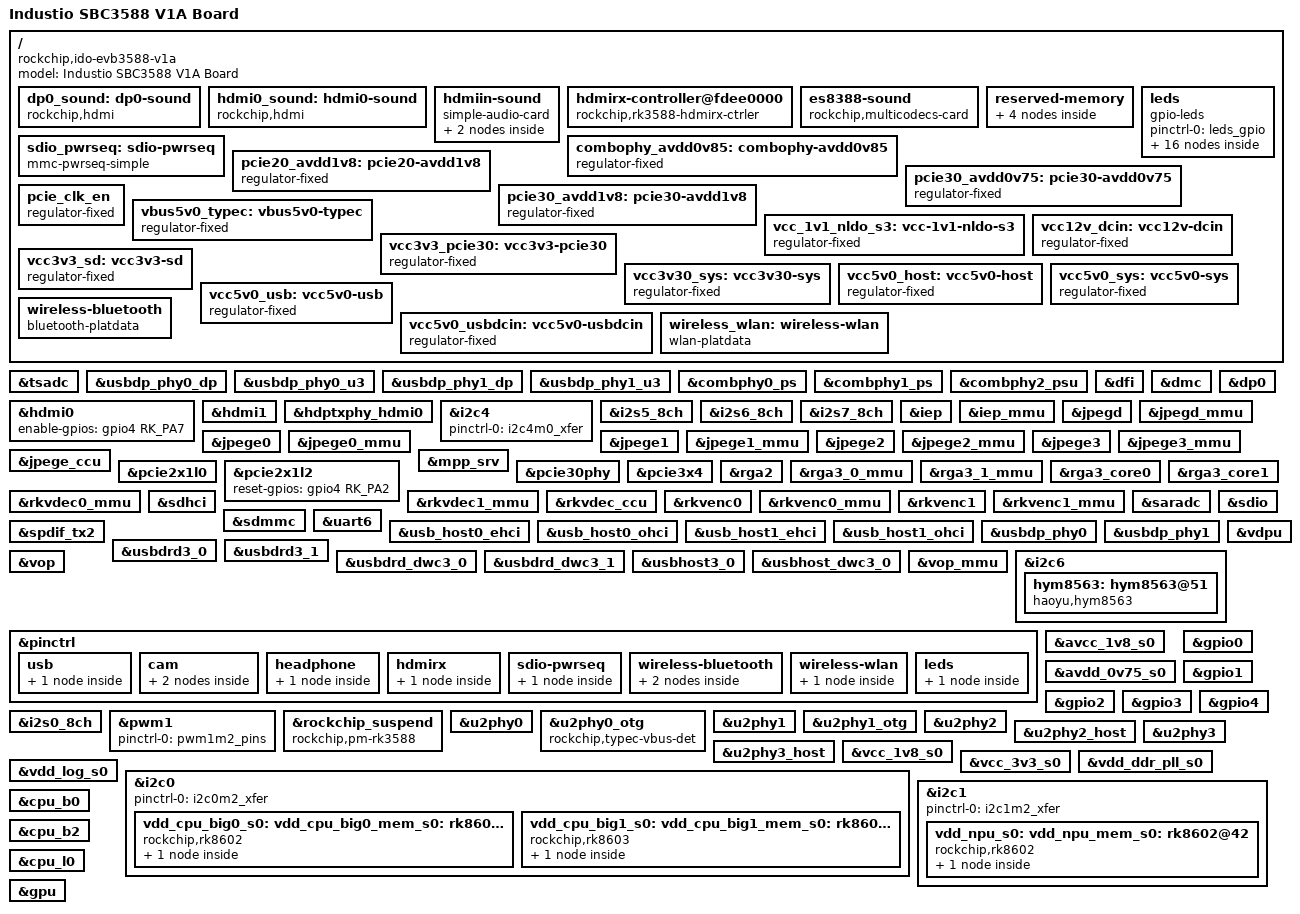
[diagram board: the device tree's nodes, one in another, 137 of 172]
// SPDX-License-Identifier: (GPL-2.0+ OR MIT)
/dts-v1/;
#include "rk3588.dtsi"
#include "rk3588-rk806-single.dtsi"

/ {
	model = "Industio SBC3588 V1A Board";
	compatible = "rockchip,ido-evb3588-v1a", "rockchip,rk3588";

	dp0_sound: dp0-sound {
	        status = "okay";
	        compatible = "rockchip,hdmi";
	        rockchip,card-name = "rockchip,dp0";
	        rockchip,mclk-fs = <512>;
	        rockchip,cpu = <&spdif_tx2>;
	        rockchip,codec = <&dp0 0x01>;
	        rockchip,jack-det;
	    };

	hdmi0_sound: hdmi0-sound {
	        status = "okay";
	        compatible = "rockchip,hdmi";
	        rockchip,mclk-fs = <128>;
	        rockchip,card-name = "rockchip-hdmi0";
	        rockchip,cpu = <&i2s5_8ch>;
	        rockchip,codec = <&hdmi0>;
	        rockchip,jack-det;
	    };

	hdmiin-sound {
	        compatible = "simple-audio-card";
	        simple-audio-card,format = "i2s";
	        simple-audio-card,name = "rockchip,hdmiin";
	        simple-audio-card,bitclock-master = <455>;
	        simple-audio-card,frame-master = <455>;
	        status = "okay";

	        simple-audio-card,cpu {
	            sound-dai = <456>;
	        };

	        simple-audio-card,codec {
	            sound-dai = <457>;
	            phandle = <0x1c7>;
	        };
	    };

	hdmirx-controller@fdee0000 {
	        compatible = "rockchip,rk3588-hdmirx-ctrler", "rockchip,hdmirx-ctrler";
	        reg = <0x00 0xfdee0000 0x00 0x6000>;
	        reg-names = "hdmirx_regs";
	        power-domains = <81 26>;
	        rockchip,grf = <187>;
	        rockchip,vo1_grf = <192>;
	        interrupts = <0x00 0xb1 0x04 0x00 0x1b4 0x04 0x00 0xb3 0x04>;
	        interrupt-names = "cec", "hdmi", "dma";
	        clocks = <0x02 538 0x02 543 0x02 690 0x02 539 0x02 540 0x02 562 0x05>;
	        clock-names = "aclk", "audio", "cr_para", "pclk", "ref", "hclk_s_hdmirx", "hclk_vo1";
	        resets = <0x02 985 0x02 986 0x02 987 0x02 951>;
	        reset-names = "rst_a", "rst_p", "rst_ref", "rst_biu";
	        pinctrl-0 = <&hdmim1_rx &hdmirx_det>;
	        pinctrl-names = "default";
	        status = "okay";
	        hpd-trigger-level = <0x01>;
	        hdmirx-det-gpios = <&gpio1 RK_PD5 GPIO_ACTIVE_LOW>;
	    };

	es8388-sound {
	        status = "okay";
	        compatible = "rockchip,multicodecs-card";
	        rockchip,card-name = "rockchip-es8388";
	        hp-det-gpio = <&gpio1 RK_PC4 GPIO_ACTIVE_HIGH>;
	        io-channels = <&saradc 0x03>;
	        io-channel-names = "adc-detect";
	        keyup-threshold-microvolt = <970000>;
	        poll-interval = <100>;
	        spk-con-gpio = <0x1ba 0x01 0x01>;
	        hp-con-gpio = <0x16d 0x1a 0x00>;
	        rockchip,format = "i2s";
	        rockchip,mclk-fs = <256>;
	        rockchip,cpu = <&i2s0_8ch>;
	        rockchip,codec = <459>;
	        rockchip,audio-routing = "Headphone", "LOUT1", "Headphone", "ROUT1", "Speaker", "LOUT2", "Speaker", "ROUT2", "Headphone", "Headphone Power", "Headphone", "Headphone Power", "Speaker", "Speaker Power", "Speaker", "Speaker Power", "LINPUT1", "Main Mic", "LINPUT2", "Main Mic", "RINPUT1", "Headset Mic", "RINPUT2", "Headset Mic";
	        pinctrl-names = "default";
	        pinctrl-0 = <&hp_det>;
	    };

	reserved-memory {
	        #address-cells = <0x02>;
	        #size-cells = <0x02>;
	        ranges;

	        cma {
	            compatible = "shared-dma-pool";
	            reusable;
	            size = <0x00 0x800000>;
	            linux,cma-default;
	            reg = <0x00 0x10000000 0x00 0x8000000>;
	        };

	        drm-logo@00000000 {
	            compatible = "rockchip,drm-logo";
	            reg = <0x00 0xedf00000 0x00 0xb7388>;
	            phandle = <0x30>;
	        };

	        drm-cubic-lut@00000000 {
	            compatible = "rockchip,drm-cubic-lut";
	            reg = <0x00 0x00 0x00 0x00>;
	        };

	        ramoops@110000 {
	            compatible = "ramoops";
	            reg = <0x00 0x110000 0x00 0xf0000>;
	            record-size = <131072>;
	            console-size = <524288>;
	            ftrace-size = <0x00>;
	            pmsg-size = <327680>;
	        };
	    };

	leds {
	        compatible = "gpio-leds";
	        status = "okay";
	        pinctrl-names = "default";
	        pinctrl-0 = <&leds_gpio>;

	        work {
	            gpios = <&gpio3 RK_PB7 GPIO_ACTIVE_HIGH>;
	            linux,default-trigger = "heartbeat";
	        };

	        heartbeat {
	            gpios = <&gpio0 RK_PB0 GPIO_ACTIVE_HIGH>;
	            linux,default-trigger = "heartbeat";
	        };

	        edp_on {
	            gpios = <&i2c8 RK_PB6 GPIO_ACTIVE_HIGH>;
	            default-state = "on";
	        };

	        fan {
	            gpios = <&i2c8 RK_PA2 GPIO_ACTIVE_HIGH>;
	            default-state = "on";
	        };

	        usb_host1_pwr {
	            gpios = <&i2c8 RK_PB0 GPIO_ACTIVE_HIGH>;
	            default-state = "on";
	        };

	        usb_host2_pwr {
	            gpios = <&i2c8 RK_PB1 GPIO_ACTIVE_HIGH>;
	            default-state = "on";
	        };

	        usb_host3_pwr {
	            gpios = <&i2c8 RK_PA3 GPIO_ACTIVE_HIGH>;
	            default-state = "on";
	        };

	        usb_host4_pwr {
	            gpios = <&i2c8 RK_PA4 GPIO_ACTIVE_HIGH>;
	            default-state = "on";
	        };

	        host_J52 {
	            gpios = <&i2c8 RK_PB2 GPIO_ACTIVE_HIGH>;
	            default-state = "on";
	        };

	        host_J53 {
	            gpios = <&i2c8 RK_PA6 GPIO_ACTIVE_HIGH>;
	            default-state = "on";
	        };

	        host_J54 {
	            gpios = <&i2c8 RK_PA5 GPIO_ACTIVE_HIGH>;
	            default-state = "on";
	        };

	        host_J55 {
	            gpios = <&i2c8 RK_PB3 GPIO_ACTIVE_HIGH>;
	            default-state = "on";
	        };

	        host_J56 {
	            gpios = <&gpio0 RK_PA0 GPIO_ACTIVE_HIGH>;
	            default-state = "on";
	        };

	        host_J90 {
	            gpios = <&gpio1 RK_PC6 GPIO_ACTIVE_HIGH>;
	            default-state = "on";
	        };

	        host_J91 {
	            gpios = <&gpio2 RK_PC5 GPIO_ACTIVE_HIGH>;
	            default-state = "on";
	        };

	        lte_pwr {
	            gpios = <&gpio4 RK_PC2 GPIO_ACTIVE_HIGH>;
	            default-state = "on";
	        };
	    };

	sdio_pwrseq: sdio-pwrseq {
	        compatible = "mmc-pwrseq-simple";
	        clocks = <&hym8563>;
	        assigned-clocks = <0x02 674>;
	        assigned-clock-rates = <32768>;
	        clock-names = "ext_clock";
	        pinctrl-names = "default";
	        pinctrl-0 = <&wifi_enable_h>;
	        pinctrl-2 = <&clk32k_out1>;
	        post-power-on-delay-ms = <200>;
	        reset-gpios = <&gpio0 RK_PC7 GPIO_ACTIVE_LOW>;
	        phandle = <0x104>;
	    };

	combophy_avdd0v85: combophy-avdd0v85 {
	        compatible = "regulator-fixed";
	        regulator-name = "combophy_avdd0v85";
	        regulator-boot-on;
	        regulator-always-on;
	        regulator-min-microvolt = <850000>;
	        regulator-max-microvolt = <850000>;
	        vin-supply = <&vdd_0v85_s0>;
	    };

	pcie20_avdd1v8: pcie20-avdd1v8 {
	        compatible = "regulator-fixed";
	        regulator-name = "pcie20_avdd1v8";
	        regulator-boot-on;
	        regulator-always-on;
	        regulator-min-microvolt = <1800000>;
	        regulator-max-microvolt = <1800000>;
	        vin-supply = <&avcc_1v8_s0>;
	    };

	pcie30_avdd0v75: pcie30-avdd0v75 {
	        compatible = "regulator-fixed";
	        regulator-name = "pcie30_avdd0v75";
	        regulator-boot-on;
	        regulator-always-on;
	        regulator-min-microvolt = <750000>;
	        regulator-max-microvolt = <750000>;
	        vin-supply = <&avdd_0v75_s0>;
	    };

	pcie30_avdd1v8: pcie30-avdd1v8 {
	        compatible = "regulator-fixed";
	        regulator-name = "pcie30_avdd1v8";
	        regulator-boot-on;
	        regulator-always-on;
	        regulator-min-microvolt = <1800000>;
	        regulator-max-microvolt = <1800000>;
	        vin-supply = <&avcc_1v8_s0>;
	    };

	pcie_clk_en: pcie_clk_en {
	        compatible = "regulator-fixed";
	        regulator-name = "pcie_clk_en";
	        regulator-min-microvolt = <3300000>;
	        regulator-max-microvolt = <3300000>;
	        enable-active-low;
	        regulator-always-on;
	        gpios = <&gpio4 RK_PB4 GPIO_ACTIVE_LOW>;
	    };

	vbus5v0_typec: vbus5v0-typec {
	        compatible = "regulator-fixed";
	        regulator-name = "vbus5v0_typec";
	        regulator-min-microvolt = <5000000>;
	        regulator-max-microvolt = <5000000>;
	        enable-active-high;
	        gpio = <&gpio1 RK_PD3 GPIO_ACTIVE_HIGH>;
	        vin-supply = <&vcc5v0_usb>;
	        pinctrl-names = "default";
	        pinctrl-0 = <&typec0_5v_pwren>;
	        phandle = <0x12f>;
	    };

	vcc_1v1_nldo_s3: vcc-1v1-nldo-s3 {
	        compatible = "regulator-fixed";
	        regulator-name = "vcc_1v1_nldo_s3";
	        regulator-always-on;
	        regulator-boot-on;
	        regulator-min-microvolt = <1100000>;
	        regulator-max-microvolt = <1100000>;
	        vin-supply = <&vcc5v0_sys>;
	        phandle = <0x147>;
	    };

	vcc12v_dcin: vcc12v-dcin {
	        compatible = "regulator-fixed";
	        regulator-name = "vcc12v_dcin";
	        regulator-always-on;
	        regulator-boot-on;
	        regulator-min-microvolt = <12000000>;
	        regulator-max-microvolt = <12000000>;
	        phandle = <0x1c0>;
	    };

	vcc3v3_pcie30: vcc3v3-pcie30 {
	        compatible = "regulator-fixed";
	        regulator-name = "vcc3v3_pcie30";
	        regulator-min-microvolt = <3300000>;
	        regulator-max-microvolt = <3300000>;
	        enable-active-high;
	        gpios = <&gpio4 RK_PB5 GPIO_ACTIVE_HIGH>;
	        startup-delay-us = <5000>;
	        vin-supply = <&vcc5v0_sys>;
	        phandle = <0x1a1>;
	    };

	vcc3v3_sd: vcc3v3-sd {
	        compatible = "regulator-fixed";
	        regulator-name = "vcc3v3_sd";
	        regulator-boot-on;
	        regulator-always-on;
	        enable-active-high;
	        gpio = <&gpio0 RK_PB2 GPIO_ACTIVE_HIGH>;
	        phandle = <0x102>;
	    };

	vcc3v30_sys: vcc3v30-sys {
	        compatible = "regulator-fixed";
	        regulator-name = "vcc3v30_sys";
	        regulator-always-on;
	        regulator-boot-on;
	        regulator-min-microvolt = <3300000>;
	        regulator-max-microvolt = <3300000>;
	        vin-supply = <&vcc5v0_sys>;
	    };

	vcc5v0_host: vcc5v0-host {
	        compatible = "regulator-fixed";
	        regulator-name = "vcc5v0_host";
	        regulator-boot-on;
	        regulator-always-on;
	        regulator-min-microvolt = <5000000>;
	        regulator-max-microvolt = <5000000>;
	        vin-supply = <&vcc5v0_usb>;
	        phandle = <0x64>;
	    };

	vcc5v0_sys: vcc5v0-sys {
	        compatible = "regulator-fixed";
	        regulator-name = "vcc5v0_sys";
	        regulator-always-on;
	        regulator-boot-on;
	        regulator-min-microvolt = <5000000>;
	        regulator-max-microvolt = <5000000>;
	        vin-supply = <&vcc12v_dcin>;
	        phandle = <0x67>;
	    };

	vcc5v0_usb: vcc5v0-usb {
	        compatible = "regulator-fixed";
	        regulator-name = "vcc5v0_usb";
	        regulator-always-on;
	        regulator-boot-on;
	        regulator-min-microvolt = <5000000>;
	        regulator-max-microvolt = <5000000>;
	        vin-supply = <&vcc5v0_usbdcin>;
	        phandle = <0x1c5>;
	    };

	vcc5v0_usbdcin: vcc5v0-usbdcin {
	        compatible = "regulator-fixed";
	        regulator-name = "vcc5v0_usbdcin";
	        regulator-always-on;
	        regulator-boot-on;
	        regulator-min-microvolt = <5000000>;
	        regulator-max-microvolt = <5000000>;
	        vin-supply = <&vcc12v_dcin>;
	        phandle = <0x1c1>;
	    };

	wireless-bluetooth {
	        compatible = "bluetooth-platdata";
	        clocks = <0x02 674>;
	        clock-names = "ext_clock";
	        uart_rts_gpios = <0xe7 0x14 0x01>;
	        pinctrl-names = "default", "rts_gpio";
	        pinctrl-0 = <&uart9m0_rtsn &bt_gpio>;
	        pinctrl-1 = <&uart9_gpios>;
	        BT,reset_gpio = <0xf5 0x16 0x00>;
	        BT,wake_gpio = <0x1bb 0x11 0x00>;
	        BT,wake_host_irq = <443 0x0e 0x00>;
	        status = "okay";
	    };

	wireless_wlan: wireless-wlan {
	        compatible = "wlan-platdata";
	        wifi_chip_type = "ap6255";
	        pinctrl-names = "default";
	        pinctrl-0 = <&wifi_host_wake_irq>;
	        WIFI,host_wake_irq = <&gpio4 RK_PC6 GPIO_ACTIVE_HIGH>;
	        status = "okay";
	    };
};

&tsadc {
	status = "okay";
};

&usbdp_phy0_dp {
	status = "okay";
};

&usbdp_phy0_u3 {
	status = "okay";
};

&usbdp_phy1_dp {
	status = "okay";
};

&usbdp_phy1_u3 {
	status = "okay";
};

&combphy0_ps {
	status = "okay";
};

&combphy1_ps {
	status = "okay";
};

&combphy2_psu {
	status = "okay";
};

&dfi {
	status = "okay";
};

&dmc {
	center-supply = <&vdd_ddr_s0>;
	mem-supply = <&vdd_log_s0>;
	status = "okay";
};

&dp0 {
	status = "okay";
};

&hdmi0 {
	enable-gpios = <&gpio4 RK_PA7 GPIO_ACTIVE_HIGH>;
	phandle = <0x1b2>;
	status = "okay";
};

&hdmi1 {
	phandle = <0x1b4>;
	pinctrl-0 = <&hdmim2_tx1_cec &hdmim0_tx1_hpd &hdmim1_tx1_scl &hdmim1_tx1_sda>;
	pinctrl-names = "default";
};

&hdptxphy_hdmi0 {
	status = "okay";
};

&i2c4 {
	pinctrl-0 = <&i2c4m0_xfer>;
	pinctrl-names = "default";
};

&i2s5_8ch {
	status = "okay";
};

&i2s6_8ch {
	status = "okay";
};

&i2s7_8ch {
	status = "okay";
};

&iep {
	status = "okay";
};

&iep_mmu {
	status = "okay";
};

&jpegd {
	status = "okay";
};

&jpegd_mmu {
	status = "okay";
};

&jpege0 {
	status = "okay";
};

&jpege0_mmu {
	status = "okay";
};

&jpege1 {
	status = "okay";
};

&jpege1_mmu {
	status = "okay";
};

&jpege2 {
	status = "okay";
};

&jpege2_mmu {
	status = "okay";
};

&jpege3 {
	status = "okay";
};

&jpege3_mmu {
	status = "okay";
};

&jpege_ccu {
	status = "okay";
};

&mpp_srv {
	status = "okay";
};

&pcie2x1l0 {
	phandle = <0x1a3>;
};

&pcie2x1l2 {
	phandle = <0xf0>;
	reset-gpios = <&gpio4 RK_PA2 GPIO_ACTIVE_HIGH>;
	status = "okay";
};

&pcie30phy {
	status = "okay";
};

&pcie3x4 {
	phandle = <0x19e>;
	reset-gpios = <&gpio4 RK_PB6 GPIO_ACTIVE_HIGH>;
	status = "okay";
	vpcie3v3-supply = <&vcc3v3_pcie30>;
};

&rga2 {
	status = "okay";
};

&rga3_0_mmu {
	status = "okay";
};

&rga3_1_mmu {
	status = "okay";
};

&rga3_core0 {
	status = "okay";
};

&rga3_core1 {
	status = "okay";
};

&rkvdec0_mmu {
	status = "okay";
};

&rkvdec1_mmu {
	status = "okay";
};

&rkvdec_ccu {
	status = "okay";
};

&rkvenc0 {
	status = "okay";
};

&rkvenc0_mmu {
	status = "okay";
};

&rkvenc1 {
	status = "okay";
};

&rkvenc1_mmu {
	status = "okay";
};

&saradc {
	status = "okay";
};

&sdhci {
	bus-width = <0x08>;
	max-frequency = <200000000>;
	mmc-hs400-1_8v;
	mmc-hs400-enhanced-strobe;
	no-sd;
	no-sdio;
	non-removable;
	status = "okay";
};

&sdio {
	bus-width = <0x04>;
	cap-sd-highspeed;
	cap-sdio-irq;
	disable-wp;
	keep-power-in-suspend;
	max-frequency = <150000000>;
	mmc-pwrseq = <&sdio_pwrseq>;
	non-removable;
	pinctrl-0 = <&sdiom0_pins>;
	pinctrl-names = "default";
	sd-uhs-sdr104;
	status = "okay";
};

&sdmmc {
	bus-width = <0x04>;
	cap-mmc-highspeed;
	cap-sd-highspeed;
	disable-wp;
	max-frequency = <150000000>;
	no-mmc;
	no-sdio;
	pinctrl-0 = <&sdmmc_clk &sdmmc_cmd &sdmmc_det &sdmmc_bus4>;
	pinctrl-names = "default";
	sd-uhs-sdr104;
	status = "okay";
	vmmc-supply = <&vcc3v3_sd>;
	vqmmc-supply = <&vccio_sd_s0>;
};

&spdif_tx2 {
	status = "okay";
};

&uart6 {
	status = "okay";
};

&usb_host0_ehci {
	status = "okay";
};

&usb_host0_ohci {
	status = "okay";
};

&usb_host1_ehci {
	status = "okay";
};

&usb_host1_ohci {
	status = "okay";
};

&usbdp_phy0 {
	orientation-switch;
	phandle = <0xdf>;
	sbu1-dc-gpios = <&gpio1 RK_PB0 GPIO_ACTIVE_HIGH>;
	sbu2-dc-gpios = <&gpio1 RK_PA6 GPIO_ACTIVE_HIGH>;
	status = "okay";
	svid = <65281>;
};

&usbdp_phy1 {
	phandle = <0x18d>;
	status = "okay";
};

&usbdrd3_0 {
	status = "okay";
};

&usbdrd3_1 {
	status = "okay";
};

&usbdrd_dwc3_0 {
	dr_mode = "otg";
	phandle = <0x130>;
	status = "okay";
	usb-role-switch;
};

&usbdrd_dwc3_1 {
	status = "okay";
};

&usbhost3_0 {
	status = "okay";
};

&usbhost_dwc3_0 {
	status = "okay";
};

&vdpu {
	status = "okay";
};

&vop {
	status = "okay";
};

&vop_mmu {
	status = "okay";
};

&i2c6 {
	status = "okay";

hym8563: hym8563@51 {
            compatible = "haoyu,hym8563";
            reg = <0x51>;
            #clock-cells = <0x00>;
            clock-frequency = <32768>;
            clock-output-names = "hym8563";
            pinctrl-names = "default";
            status = "okay";
            phandle = <0x1ce>;
        };
};

&pinctrl {
	usb {
		vcc5v0_host_en: vcc5v0-host-en {
		                rockchip,pins = <0x04 0x08 0x00 0x177>;
		            };
	};

	cam {
		mipicsi1_pwr: mipicsi1-pwr {
		                rockchip,pins = <0x01 0x0a 0x00 0x177>;
		            };
	};

	cam {
		mipidcphy0_pwr: mipidcphy0-pwr {
		                rockchip,pins = <0x02 0x14 0x00 0x177>;
		            };
	};

	headphone {
		hp_det: hp-det {
		                rockchip,pins = <0x01 0x14 0x00 0x177>;
		                phandle = <0x1cc>;
		            };
	};

	hdmirx {
		hdmirx_det: hdmirx-det {
		                rockchip,pins = <0x01 0x1d 0x00 0x17c>;
		                phandle = <0x19d>;
		            };
	};

	sdio-pwrseq {
		wifi_enable_h: wifi-enable-h {
		                rockchip,pins = <0x00 0x17 0x00 0x177>;
		                phandle = <0x1cf>;
		            };
	};

	wireless-bluetooth {
		uart9_gpios: uart9-gpios {
		                rockchip,pins = <0x04 0x14 0x00 0x177>;
		                phandle = <0x1d3>;
		            };
	};

	wireless-bluetooth {
		bt_gpio: bt-gpio {
		                rockchip,pins = <0x02 0x11 0x00 0x177 0x02 0x0e 0x00 0x17c 0x00 0x16 0x00 0x181>;
		                phandle = <0x1d2>;
		            };
	};

	wireless-wlan {
		wifi_host_wake_irq: wifi-host-wake-irq {
		                rockchip,pins = <0x04 0x16 0x00 0x181>;
		                phandle = <0x1d4>;
		            };
	};

	leds {
		leds_gpio: leds-gpio {
		                rockchip,pins = <0x00 0x00 0x00 0x177 0x00 0x08 0x00 0x177 0x02 0x15 0x00 0x177 0x01 0x16 0x00 0x177 0x04 0x12 0x00 0x177>;
		                phandle = <0x1b9>;
		            };
	};

};

&avcc_1v8_s0 {
};

&avdd_0v75_s0 {
};

&gpio0 {
	phandle = <0xf5>;
};

&gpio1 {
	phandle = <0x16d>;
};

&gpio2 {
	phandle = <0x1bb>;
};

&gpio3 {
	phandle = <0x135>;
};

&gpio4 {
	phandle = <0xe7>;
};

&i2c4 {
	pinctrl-0 = <&i2c4m0_xfer>;
	pinctrl-names = "default";
};

&i2s0_8ch {
	#sound-dai-cells = <0x00>;
	phandle = <0x1ca>;
	pinctrl-0 = <&i2s0_lrck &i2s0_sclk &i2s0_sdi0 &i2s0_sdo0>;
	pinctrl-names = "default";
	status = "okay";
};

&pwm1 {
	pinctrl-0 = <&pwm1m2_pins>;
	pinctrl-names = "active";
	status = "okay";
};

&rockchip_suspend {
	compatible = "rockchip,pm-rk3588";
	status = "okay";
	rockchip,sleep-debug-en = <1>;
	rockchip,sleep-mode-config = <
		(0
		| RKPM_SLP_ARMOFF_DDRPD
		)
	>;
	rockchip,wakeup-config = <
		(0
		| RKPM_GPIO_WKUP_EN
		| RKPM_USB_WKUP_EN
		)
	>;
};

&u2phy0 {
	status = "okay";
};

&u2phy0_otg {
	phandle = <0x56>;
	rockchip,typec-vbus-det;
	status = "okay";
};

&u2phy1 {
	status = "okay";
};

&u2phy1_otg {
	phandle = <0x189>;
	status = "okay";
};

&u2phy2 {
	status = "okay";
};

&u2phy2_host {
	status = "okay";
};

&u2phy3 {
	status = "okay";
};

&u2phy3_host {
	status = "okay";
};

&vcc_1v8_s0 {
};

&vcc_3v3_s0 {
};

&vdd_ddr_pll_s0 {
};

&vdd_log_s0 {
};

&i2c0 {
	status = "okay";

	phandle = <0x18>;
	pinctrl-0 = <&i2c0m2_xfer>;
	pinctrl-names = "default";

	vdd_cpu_big0_s0: vdd_cpu_big0_mem_s0: rk8602@42 {
		compatible = "rockchip,rk8602";
		reg = <0x42>;
		regulator-always-on;
		regulator-boot-on;
		regulator-compatible = "rk860x-reg";
		regulator-name = "vdd_cpu_big0_s0";
		regulator-min-microvolt = <550000>;
		regulator-max-microvolt = <1050000>;
		regulator-ramp-delay = <2300>;
		rockchip,suspend-voltage-selector = <0x01>;
		vin-supply = <&vcc5v0_sys>;

		regulator-state-mem {
			regulator-off-in-suspend;
		};
	};

	vdd_cpu_big1_s0: vdd_cpu_big1_mem_s0: rk8603@43 {
		compatible = "rockchip,rk8603";
		reg = <0x43>;
		regulator-always-on;
		regulator-boot-on;
		regulator-compatible = "rk860x-reg";
		regulator-name = "vdd_cpu_big1_s0";
		regulator-min-microvolt = <550000>;
		regulator-max-microvolt = <1050000>;
		regulator-ramp-delay = <2300>;
		rockchip,suspend-voltage-selector = <0x01>;
		vin-supply = <&vcc5v0_sys>;

		regulator-state-mem {
			regulator-off-in-suspend;
		};
	};
};

&i2c1 {
	status = "okay";

	phandle = <0x9f>;
	pinctrl-0 = <&i2c1m2_xfer>;
	pinctrl-names = "default";
	vdd_npu_s0: vdd_npu_mem_s0: rk8602@42 {
		compatible = "rockchip,rk8602";
		reg = <0x42>;
		regulator-always-on;
		regulator-boot-on;
		regulator-compatible = "rk860x-reg";
		regulator-name = "vdd_npu_s0";
		regulator-min-microvolt = <550000>;
		regulator-max-microvolt = <950000>;
		regulator-ramp-delay = <2300>;
		rockchip,suspend-voltage-selector = <0x01>;
		vin-supply = <&vcc5v0_sys>;

		regulator-state-mem {
			regulator-off-in-suspend;
		};
	};
};

&cpu_b0 {
	cpu-supply = <&vdd_cpu_big0_s0>;
	mem-supply = <&vdd_cpu_big0_mem_s0>;
};

&cpu_b2 {
	cpu-supply = <&vdd_cpu_big1_s0>;
	mem-supply = <&vdd_cpu_big1_mem_s0>;
};

&cpu_l0 {
	cpu-supply = <&vdd_cpu_lit_s0>;
	mem-supply = <&vdd_cpu_lit_mem_s0>;
};

&gpu {
	mali-supply = <&vdd_gpu_s0>;
	mem-supply = <&vdd_gpu_mem_s0>;
	status = "okay";
};
